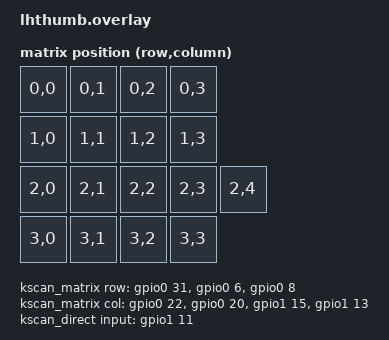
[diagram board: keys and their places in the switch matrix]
// This file was generated from a template. Edit it to match your keyboard.
// See https://zmk.dev/docs/development/hardware-integration/new-shield for more
// instructions.

#include <dt-bindings/zmk/matrix_transform.h>
#include <dt-bindings/adc/adc.h>
#include <dt-bindings/analog-stick/modes.h>
#include <zephyr/dt-bindings/gpio/gpio.h>

#include "lhthumb-layouts.dtsi"

/ {
    chosen {
        zmk,physical-layout = &default_layout;
    };

    joystick: analog_stick {
        compatible = "zmk,analog-stick";
        /*
         * X = P0.02 = AIN0
         * Y = P0.29 = AIN5
         */
        io-channels = <&adc 0>, <&adc 1>;

        x-center = <2048>;
        x-min = <0>;
        x-max = <4095>;

        y-center = <2048>;
        y-min = <0>;
        y-max = <4095>;

        deadzone-percent = <8>;
    };

    joystick_listener: joystick_listener {
        compatible = "zmk,analog-stick-listener";
        device = <&joystick>;

        layer0 {
            layers = <0>;
            mode = <ANALOG_STICK_MODE_SWITCH>;
            switch-activation-point = <40>;
            switch-hysteresis = <8>;
            up-position = <13>;
            down-position = <14>;
            left-position = <15>;
            right-position = <16>;
        };
    };


    kscan_matrix: kscan_matrix {
        compatible = "zmk,kscan-gpio-matrix";
        diode-direction = "col2row";
        wakeup-source;

        col-gpios
            = <&gpio0 22 GPIO_ACTIVE_HIGH> //A
            , <&gpio0 20 GPIO_ACTIVE_HIGH> //B
            , <&gpio1 15 GPIO_ACTIVE_HIGH> //C
            , <&gpio1 13 GPIO_ACTIVE_HIGH> //D
            ;

        row-gpios
            = <&gpio0 31 (GPIO_ACTIVE_HIGH | GPIO_PULL_DOWN)> //1
            , <&gpio0 6  (GPIO_ACTIVE_HIGH | GPIO_PULL_DOWN)> //2
            , <&gpio0 8  (GPIO_ACTIVE_HIGH | GPIO_PULL_DOWN)> //3
            ;
    };

    kscan_direct: kscan_direct {
        compatible = "zmk,kscan-gpio-direct";
        input-gpios = <&gpio1 11 (GPIO_ACTIVE_LOW | GPIO_PULL_UP)>;
    };

    kscan: kscan {
        compatible = "zmk,kscan-composite";
        rows = <4>;
        columns = <5>;

        matrix {
            kscan = <&kscan_matrix>;
            row-offset = <0>;
            col-offset = <0>;
        };

        direct {
            kscan = <&kscan_direct>;
            row-offset = <2>;
            col-offset = <4>;
        };
    };

    default_transform: default_transform {
        compatible = "zmk,matrix-transform";
        columns = <5>;
        rows = <4>;

        map = <
            RC(0,0) RC(0,1) RC(0,2) RC(0,3)
            RC(1,0) RC(1,1) RC(1,2) RC(1,3)
            RC(2,0) RC(2,1) RC(2,2) RC(2,3) RC(2,4)
            RC(3,0) RC(3,1) RC(3,2) RC(3,3)
        >;// 4 teclas virtuales para WASD  //joystick switch
    };
};

&adc {
    status = "okay";
    #address-cells = <1>;
    #size-cells = <0>;

    /* Canal 0 mapeado al pin físico P0.02 (AIN0 del nRF52840) */
    channel@0 {
        reg = <0>;
        zephyr,gain = "ADC_GAIN_1_6";
        zephyr,reference = "ADC_REF_INTERNAL";
        zephyr,acquisition-time = <ADC_ACQ_TIME_DEFAULT>;
        zephyr,resolution = <12>;
        zephyr,input-positive = <NRF_SAADC_AIN0>;
    };

    /* Canal 1 mapeado al pin físico P0.29 (AIN5 del nRF52840) */
    channel@1 {
        reg = <1>;
        zephyr,gain = "ADC_GAIN_1_6";
        zephyr,reference = "ADC_REF_INTERNAL";
        zephyr,acquisition-time = <ADC_ACQ_TIME_DEFAULT>;
        zephyr,resolution = <12>;
        zephyr,input-positive = <NRF_SAADC_AIN5>;
    };
};

